LIN_description_file;
LIN_protocol_version = "2.0";
LIN_language_version = "2.0";
LIN_speed = 19.2 kbps;

Nodes {
  Master: LIN_Commander, 1 ms, 0 ms ;
  Slaves: LIN_Responder, slave17 ;
}

Signals {
  frame17: 8, 0, LIN_Commander, LIN_Responder ;
  frame18: 8, 0, LIN_Commander, LIN_Responder ;
  frame19: 8, 0, LIN_Commander, LIN_Responder ;
}

Frames {
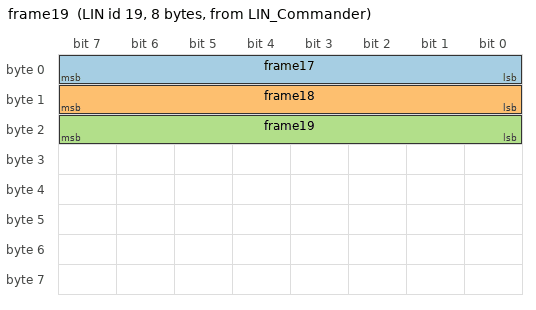
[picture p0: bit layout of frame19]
  frame19: 19, LIN_Commander, 8 {
    frame17, 0 ;
    frame18, 8 ;
    frame19, 16 ;
  }
}

Node_attributes {
  LIN_Responder{
    LIN_protocol = "2.0" ;
    configured_NAD = 0xFF ;
    product_id = 0x0, 0x0, 255 ;
    P2_min = 0 ms ;
    ST_min = 0 ms ;
    configurable_frames {
      frame19 = 0x0 ;
    }
  }
  slave17{
    LIN_protocol = "2.0" ;
    configured_NAD = 0xFF ;
    product_id = 0x0, 0x0, 255 ;
    P2_min = 0 ms ;
    ST_min = 0 ms ;
  }
}

Schedule_tables {
 schedule17 {
    frame19 delay 10 ms ;
    MasterReq delay 10 ms ;
    SlaveResp delay 10 ms ;
    SlaveResp delay 10 ms ;
  }
}

Signal_encoding_types {
  frame17_Encoding {
    physical_value, 2, 5, 1, 0 ;
  }
  frame19_Encoding {
  }
}

Signal_representation {
  frame17_Encoding: frame17 ;
  frame19_Encoding: frame19 ;
}
